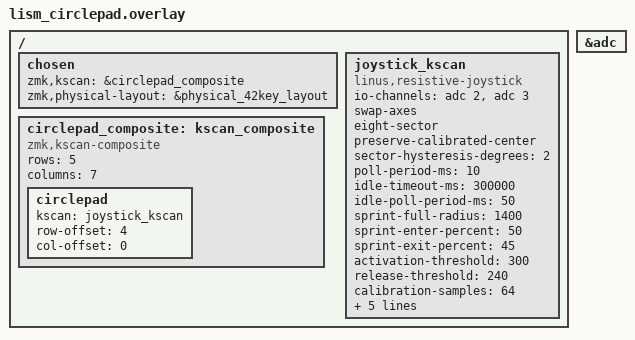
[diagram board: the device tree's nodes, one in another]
#include "lism.dtsi"
#include "lism-layouts.dtsi"

&adc {
    status = "okay";
};

/ {
    chosen {
        zmk,kscan = &circlepad_composite;
        zmk,physical-layout = &physical_42key_layout;
    };

    /* Four-wire New 3DS XL Circle Pad: X, Y, 3V3 and GND.
     * The separate BSI-10 is a power switch, not a stick push input.
     */
    joystick_kscan: joystick_kscan {
        compatible = "linus,resistive-joystick";
        io-channels = <&adc 2>, <&adc 3>; /* XIAO D4=X, D5=Y */
        swap-axes; /* Opposite long edge towards the user: pins left, USB right. */
        /* Reverse both directions of the previous trial: W<->S, A<->D.
         * No axis inversion; processed=(rawY,rawX). */
        eight-sector;
        preserve-calibrated-center; /* Discard ADC glitches; never recenter a held stick. */
        sector-hysteresis-degrees = <2>; /* Trial: nominal 45deg sectors, prior sector held 2deg. */
        poll-period-ms = <10>;
        idle-timeout-ms = <300000>;
        idle-poll-period-ms = <50>;
        sprint-full-radius = <1400>; /* Trial estimate, not mechanical travel calibration. */
        sprint-enter-percent = <50>;
        sprint-exit-percent = <45>;
        activation-threshold = <300>; /* Keep the existing larger center dead zone. */
        release-threshold = <240>; /* Trial values; verify hands-off HID release. */
        calibration-samples = <64>;
        center-min = <100>;
        center-max = <3400>;
        calibration-max-spread = <100>;
        sample-min = <40>;
        sample-max = <4000>;
    };

    circlepad_composite: kscan_composite {
        compatible = "zmk,kscan-composite";
        rows = <5>;
        columns = <7>; /* col4=optional push, col5 reserved, col6=sprint */

        circlepad {
            kscan = <&joystick_kscan>;
            row-offset = <4>;
            col-offset = <0>;
        };
    };
};
